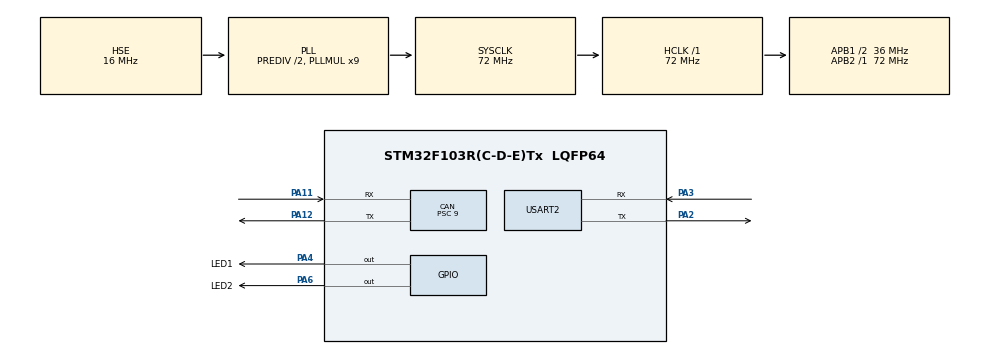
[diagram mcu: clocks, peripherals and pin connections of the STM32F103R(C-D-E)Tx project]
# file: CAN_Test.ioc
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CAN.BS1=CAN_BS1_13TQ
CAN.BS2=CAN_BS2_2TQ
CAN.CalculateBaudRate=250000
CAN.CalculateTimeBit=4000.00
CAN.CalculateTimeQuantum=250.0
CAN.Mode=CAN_MODE_NORMAL
CAN.Prescaler=9
Mcu.Family=STM32F1
Mcu.Name=STM32F103R(C-D-E)Tx
Mcu.Package=LQFP64
NVIC.CAN1_RX1_IRQn=true\:0\:0\:false\:false\:true\:true\:true
NVIC.CAN1_SCE_IRQn=true\:0\:0\:false\:false\:true\:true\:true
NVIC.PriorityGroup=NVIC_PRIORITYGROUP_4
NVIC.USART2_IRQn=true\:1\:0\:true\:false\:true\:true\:true
NVIC.USB_LP_CAN1_RX0_IRQn=true\:0\:0\:false\:false\:true\:true\:true
PA11.Mode=CAN_Activate
PA11.Signal=CAN_RX
PA12.Mode=CAN_Activate
PA12.Signal=CAN_TX
PA13.Mode=Serial_Wire
PA13.Signal=SYS_JTMS-SWDIO
PA14.Mode=Serial_Wire
PA14.Signal=SYS_JTCK-SWCLK
PA2.Mode=Asynchronous
PA2.Signal=USART2_TX
PA3.Mode=Asynchronous
PA3.Signal=USART2_RX
PA4.GPIO_Label=LED1
PA4.GPIO_PuPd=GPIO_PULLDOWN
PA4.Signal=GPIO_Output
PA6.GPIO_Label=LED2
PA6.GPIO_PuPd=GPIO_PULLDOWN
PA6.Signal=GPIO_Output
PD0-OSC_IN.Mode=HSE-External-Oscillator
PD0-OSC_IN.Signal=RCC_OSC_IN
PD1-OSC_OUT.Mode=HSE-External-Oscillator
PD1-OSC_OUT.Signal=RCC_OSC_OUT
ProjectManager.HeapSize=0x200
ProjectManager.StackSize=0x400
ProjectManager.TargetToolchain=Makefile
RCC.AHBFreq_Value=72000000
RCC.APB1CLKDivider=RCC_HCLK_DIV2
RCC.APB1Freq_Value=36000000
RCC.APB1TimFreq_Value=72000000
RCC.APB2Freq_Value=72000000
RCC.APB2TimFreq_Value=72000000
RCC.HCLKFreq_Value=72000000
RCC.HSEDivPLL=RCC_HSE_PREDIV_DIV2
RCC.HSE_VALUE=16000000
RCC.PLLMUL=RCC_PLL_MUL9
RCC.PLLSourceVirtual=RCC_PLLSOURCE_HSE
RCC.SYSCLKFreq_VALUE=72000000
RCC.SYSCLKSource=RCC_SYSCLKSOURCE_PLLCLK
RCC.USBFreq_Value=72000000
USART2.VirtualMode=VM_ASYNC
board=custom

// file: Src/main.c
/* USER CODE BEGIN Header */
/**
  ******************************************************************************
  * @file           : main.c
  * @brief          : Main program body
  ******************************************************************************
  * @attention
  *
  * <h2><center>&copy; Copyright (c) 2021 STMicroelectronics.
  * All rights reserved.</center></h2>
  *
  * This software component is licensed by ST under BSD 3-Clause license,
  * the "License"; You may not use this file except in compliance with the
  * License. You may obtain a copy of the License at:
  *                        opensource.org/licenses/BSD-3-Clause
  *
  ******************************************************************************
  */
/* USER CODE END Header */
#include "main.h"
#include "can.h"
#include "usart.h"
#include "gpio.h"

/* USER CODE BEGIN PTD */
CAN_TxHeaderTypeDef CAN_TxHeaderStruct;
CAN_RxHeaderTypeDef CAN_RxHeaderStruct;
/* USER CODE END PTD */

/* USER CODE BEGIN PV */
uint8_t TxBuffer[8] = {0x08, 0x09, 0x0A, 0x0B, 0x08, 0x09, 0x0A, 0x0B};
uint8_t RxBuffer[8] = {0};
/* USER CODE END PV */

void SystemClock_Config(void);

int main(void)
{

  /* MCU Configuration--------------------------------------------------------*/

  /* Reset of all peripherals, Initializes the Flash interface and the Systick. */
  HAL_Init();

  /* USER CODE BEGIN Init */
  uint32_t Tx_MailBox;
  /* USER CODE END Init */

  /* Configure the system clock */
  SystemClock_Config();

  /* Initialize all configured peripherals */
  MX_GPIO_Init();
  MX_CAN_Init();
  MX_USART2_UART_Init();
  /* USER CODE BEGIN 2 */
  myCAN_Init();
  /* USER CODE END 2 */

  /* Infinite loop */
  while (1)
  {

    /* USER CODE BEGIN 3 */
    HAL_CAN_AddTxMessage(&hcanHandle, &CAN_TxHeaderStruct, TxBuffer, &Tx_MailBox);
    HAL_Delay(500);
    // HAL_CAN_GetRxMessage(&hcan1, CAN_RX_FIFO0, &CAN_RxHeaderStruct, RxBuffer);
  }
  /* USER CODE END 3 */
}

void SystemClock_Config(void)
{
  RCC_OscInitTypeDef RCC_OscInitStruct = {0};
  RCC_ClkInitTypeDef RCC_ClkInitStruct = {0};

  /** Initializes the RCC Oscillators according to the specified parameters
  * in the RCC_OscInitTypeDef structure.
  */
  RCC_OscInitStruct.OscillatorType = RCC_OSCILLATORTYPE_HSE;
  RCC_OscInitStruct.HSEState = RCC_HSE_ON;
  RCC_OscInitStruct.HSEPredivValue = RCC_HSE_PREDIV_DIV2;
  RCC_OscInitStruct.HSIState = RCC_HSI_ON;
  RCC_OscInitStruct.PLL.PLLState = RCC_PLL_ON;
  RCC_OscInitStruct.PLL.PLLSource = RCC_PLLSOURCE_HSE;
  RCC_OscInitStruct.PLL.PLLMUL = RCC_PLL_MUL9;
  if (HAL_RCC_OscConfig(&RCC_OscInitStruct) != HAL_OK)
  {
    Error_Handler();
  }
  /** Initializes the CPU, AHB and APB buses clocks
  */
  RCC_ClkInitStruct.ClockType = RCC_CLOCKTYPE_HCLK|RCC_CLOCKTYPE_SYSCLK
                              |RCC_CLOCKTYPE_PCLK1|RCC_CLOCKTYPE_PCLK2;
  RCC_ClkInitStruct.SYSCLKSource = RCC_SYSCLKSOURCE_PLLCLK;
  RCC_ClkInitStruct.AHBCLKDivider = RCC_SYSCLK_DIV1;
  RCC_ClkInitStruct.APB1CLKDivider = RCC_HCLK_DIV2;
  RCC_ClkInitStruct.APB2CLKDivider = RCC_HCLK_DIV1;

  if (HAL_RCC_ClockConfig(&RCC_ClkInitStruct, FLASH_LATENCY_2) != HAL_OK)
  {
    Error_Handler();
  }
}

void Error_Handler(void)
{
  __disable_irq();
  while (1)
  {
  }
}

/************************ (C) COPYRIGHT STMicroelectronics *****END OF FILE****/
